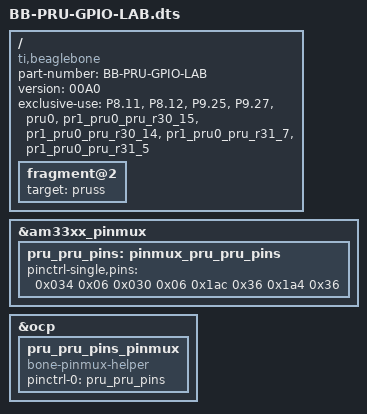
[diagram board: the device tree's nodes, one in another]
/dts-v1/;
/plugin/;

/{
    compatible = "ti,beaglebone", "ti,beaglebone-black";
    part-number = "BB-PRU-GPIO-LAB";
    version = "00A0";

    exclusive-use = "P8.11", "P8.12", "P9.25", "P9.27", "pru0",
        "pr1_pru0_pru_r30_15", "pr1_pru0_pru_r30_14", "pr1_pru0_pru_r31_7",
        "pr1_pru0_pru_r31_5";

    fragment@0 {
        target = <&am33xx_pinmux>;
        __overlay__ {
            pru_pru_pins: pinmux_pru_pru_pins {
                pinctrl-single,pins = <
                    0x034 0x06 // P8_11 pr1_pru0_pru_r30_15, Mode6 output pull‐down
                    0x030 0x06 // P8_12 pr1_pru0_pru_r30_14, Mode6 output pull‐down
                    0x1ac 0x36 // P9_25 pr1_pru0_pru_r31_7, Mode6 input pull-up
                    0x1a4 0x36 // P9_27 pr1_pru0_pru_r31_5, Mode6 input pull-up
                >;
            };
        };
    };

    fragment@1 {
        target = <&ocp>;
        __overlay__ {
            pru_pru_pins_pinmux {
                compatible = "bone-pinmux-helper";
                status = "okay";
                pinctrl-names = "default";
                pinctrl-0 = <&pru_pru_pins>;
            };
        };
    };


	fragment@2 {
		 // Enable the PRUSS
		target = <&pruss>;
	};
};
